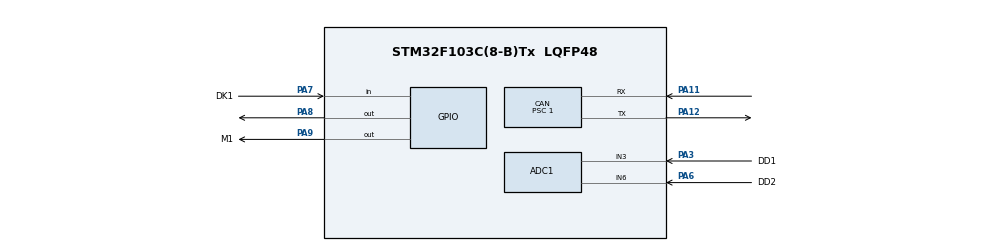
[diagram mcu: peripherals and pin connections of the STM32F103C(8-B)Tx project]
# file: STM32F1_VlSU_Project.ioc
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ADC1.Channel-0\#ChannelRegularConversion=ADC_CHANNEL_3
ADC1.Channel-1\#ChannelRegularConversion=ADC_CHANNEL_6
ADC1.Channel-2\#ChannelRegularConversion=ADC_CHANNEL_VREFINT
ADC1.ContinuousConvMode=DISABLE
ADC1.ExternalTrigConv=ADC_EXTERNALTRIGCONV_T3_TRGO
ADC1.NbrOfConversion=3
ADC1.NbrOfConversionFlag=1
ADC1.Rank-0\#ChannelRegularConversion=1
ADC1.Rank-1\#ChannelRegularConversion=2
ADC1.Rank-2\#ChannelRegularConversion=3
ADC1.SamplingTime-0\#ChannelRegularConversion=ADC_SAMPLETIME_239CYCLES_5
ADC1.SamplingTime-1\#ChannelRegularConversion=ADC_SAMPLETIME_239CYCLES_5
ADC1.SamplingTime-2\#ChannelRegularConversion=ADC_SAMPLETIME_239CYCLES_5
ADC1.master=1
CAN.BS1=CAN_BS1_13TQ
CAN.BS2=CAN_BS2_2TQ
CAN.CalculateBaudRate=500000
CAN.CalculateTimeBit=2000.00
CAN.CalculateTimeQuantum=125.0
CAN.Prescaler=1
Dma.ADC1.0.Direction=DMA_PERIPH_TO_MEMORY
Dma.ADC1.0.Instance=DMA1_Channel1
Dma.ADC1.0.MemDataAlignment=DMA_MDATAALIGN_HALFWORD
Dma.ADC1.0.MemInc=DMA_MINC_ENABLE
Dma.ADC1.0.Mode=DMA_CIRCULAR
Dma.ADC1.0.PeriphDataAlignment=DMA_PDATAALIGN_HALFWORD
Dma.ADC1.0.PeriphInc=DMA_PINC_DISABLE
Dma.ADC1.0.Priority=DMA_PRIORITY_LOW
Dma.Request0=ADC1
FREERTOS.BinarySemaphores01=myBinarySem01,Dynamic,NULL
FREERTOS.CountingSemaphores01=myCountingSem01,2,Static,myCountingSem01ControlBlock
FREERTOS.INCLUDE_xQueueGetMutexHolder=0
FREERTOS.INCLUDE_xSemaphoreGetMutexHolder=1
FREERTOS.Tasks01=defaultTask,0,128,StartDefaultTask,Default,NULL,Dynamic,NULL,NULL
FREERTOS.configUSE_COUNTING_SEMAPHORES=1
FREERTOS.configUSE_CO_ROUTINES=1
FREERTOS.configUSE_RECURSIVE_MUTEXES=1
Mcu.Family=STM32F1
Mcu.Name=STM32F103C(8-B)Tx
Mcu.Package=LQFP48
NVIC.DMA1_Channel1_IRQn=true\:5\:0\:false\:false\:true\:true\:false\:true
NVIC.PriorityGroup=NVIC_PRIORITYGROUP_4
PA11.Mode=CAN_Activate
PA11.Signal=CAN_RX
PA12.Mode=CAN_Activate
PA12.Signal=CAN_TX
PA13.Mode=Serial_Wire
PA13.Signal=SYS_JTMS-SWDIO
PA14.Mode=Serial_Wire
PA14.Signal=SYS_JTCK-SWCLK
PA3.GPIO_Label=DD1
PA3.Signal=ADCx_IN3
PA6.GPIO_Label=DD2
PA6.Signal=ADCx_IN6
PA7.GPIO_Label=DK1
PA7.Signal=GPIO_Input
PA8.Signal=GPIO_Output
PA9.GPIO_Label=M1
PA9.Signal=GPIO_Output
ProjectManager.HeapSize=0x200
ProjectManager.StackSize=0x400
ProjectManager.TargetToolchain=STM32CubeIDE
RCC.APB1Freq_Value=8000000
RCC.APB2Freq_Value=8000000
SH.ADCx_IN3.0=ADC1_IN3,IN3
SH.ADCx_IN6.0=ADC1_IN6,IN6
TIM3.Period=1024
TIM3.Prescaler=0
TIM3.TIM_MasterOutputTrigger=TIM_TRGO_UPDATE
VP_ADC1_Vref_Input.Mode=IN-Vrefint
VP_FREERTOS_VS_CMSIS_V1.Mode=CMSIS_V1
VP_TIM3_VS_ClockSourceINT.Mode=Internal
board=custom

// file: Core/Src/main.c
/* USER CODE BEGIN Header */
/**
  ******************************************************************************
  * @file           : main.c
  * @brief          : Main program body
  ******************************************************************************
  * @attention
  *
  * <h2><center>&copy; Copyright (c) 2022 STMicroelectronics.
  * All rights reserved.</center></h2>
  *
  * This software component is licensed by ST under BSD 3-Clause license,
  * the "License"; You may not use this file except in compliance with the
  * License. You may obtain a copy of the License at:
  *                        opensource.org/licenses/BSD-3-Clause
  *
  ******************************************************************************
  */
/* USER CODE END Header */
#include "main.h"
#include "cmsis_os.h"
#include "adc.h"
#include "can.h"
#include "dma.h"
#include "tim.h"
#include "gpio.h"

/* USER CODE BEGIN Includes */
#include "sensor_manager.h"
/* USER CODE END Includes */

void SystemClock_Config(void);
void MX_FREERTOS_Init(void);

/* USER CODE BEGIN 0 */
result_sensor result;
uint16_t adc_data[ADC_CHANNELS_NUM];
/* USER CODE END 0 */

int main(void)
{

  /* MCU Configuration--------------------------------------------------------*/

  /* Reset of all peripherals, Initializes the Flash interface and the Systick. */
  HAL_Init();

  /* Configure the system clock */
  SystemClock_Config();

  /* Initialize all configured peripherals */
  MX_GPIO_Init();
  MX_DMA_Init();
  MX_ADC1_Init();
  MX_TIM3_Init();
  MX_CAN_Init();
  /* USER CODE BEGIN 2 */

  HAL_TIM_Base_Start(&htim3);
  HAL_ADCEx_Calibration_Start(&hadc1);
  HAL_ADC_Start_DMA(&hadc1, (uint32_t*)adc_data, ADC_CHANNELS_NUM);

  /* USER CODE END 2 */

  /* Call init function for freertos objects (in freertos.c) */
  MX_FREERTOS_Init();
  /* Start scheduler */
  osKernelStart();

  /* We should never get here as control is now taken by the scheduler */
  /* Infinite loop */
  /* USER CODE BEGIN WHILE */
  while (1)
  {
	  get_result_sensor(&result);
	  show_result(&result);

    /* USER CODE END WHILE */

  }
}

void SystemClock_Config(void)
{
  RCC_OscInitTypeDef RCC_OscInitStruct = {0};
  RCC_ClkInitTypeDef RCC_ClkInitStruct = {0};
  RCC_PeriphCLKInitTypeDef PeriphClkInit = {0};

  /** Initializes the RCC Oscillators according to the specified parameters
  * in the RCC_OscInitTypeDef structure.
  */
  RCC_OscInitStruct.OscillatorType = RCC_OSCILLATORTYPE_HSI;
  RCC_OscInitStruct.HSIState = RCC_HSI_ON;
  RCC_OscInitStruct.HSICalibrationValue = RCC_HSICALIBRATION_DEFAULT;
  RCC_OscInitStruct.PLL.PLLState = RCC_PLL_NONE;
  if (HAL_RCC_OscConfig(&RCC_OscInitStruct) != HAL_OK)
  {
    Error_Handler();
  }
  /** Initializes the CPU, AHB and APB buses clocks
  */
  RCC_ClkInitStruct.ClockType = RCC_CLOCKTYPE_HCLK|RCC_CLOCKTYPE_SYSCLK
                              |RCC_CLOCKTYPE_PCLK1|RCC_CLOCKTYPE_PCLK2;
  RCC_ClkInitStruct.SYSCLKSource = RCC_SYSCLKSOURCE_HSI;
  RCC_ClkInitStruct.AHBCLKDivider = RCC_SYSCLK_DIV1;
  RCC_ClkInitStruct.APB1CLKDivider = RCC_HCLK_DIV1;
  RCC_ClkInitStruct.APB2CLKDivider = RCC_HCLK_DIV1;

  if (HAL_RCC_ClockConfig(&RCC_ClkInitStruct, FLASH_LATENCY_0) != HAL_OK)
  {
    Error_Handler();
  }
  PeriphClkInit.PeriphClockSelection = RCC_PERIPHCLK_ADC;
  PeriphClkInit.AdcClockSelection = RCC_ADCPCLK2_DIV2;
  if (HAL_RCCEx_PeriphCLKConfig(&PeriphClkInit) != HAL_OK)
  {
    Error_Handler();
  }
}

void Error_Handler(void)
{
  __disable_irq();
  while (1)
  {
  }
}

/************************ (C) COPYRIGHT STMicroelectronics *****END OF FILE****/
